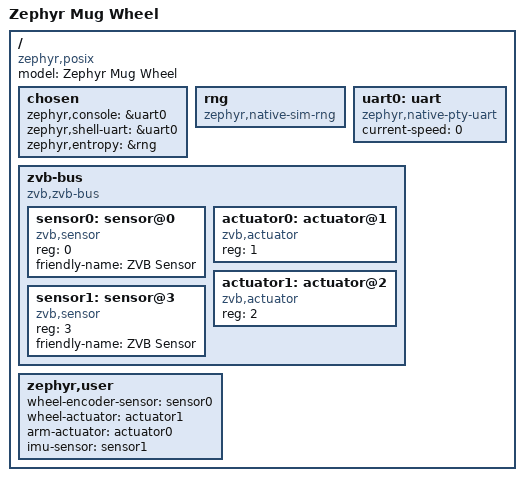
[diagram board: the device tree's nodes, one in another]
/*
 * Copyright 2025 Nordic Semiconductor ASA
 *
 * SPDX-License-Identifier: Apache-2.0
 */

/dts-v1/;
#include <posix/posix.dtsi>

/ {
	model = "Zephyr Mug Wheel";
	compatible = "zephyr,posix";

	chosen {
		zephyr,console = &uart0;
		zephyr,shell-uart = &uart0;
		zephyr,entropy = &rng;
	};

	rng: rng {
		status = "okay";
		compatible = "zephyr,native-sim-rng";
	};

	uart0: uart {
		status = "okay";
		compatible = "zephyr,native-pty-uart";
		current-speed = <0>;
	};

	zvb-bus {
		compatible = "zvb,zvb-bus";
		#address-cells = <1>;
		#size-cells = <0>;

		sensor0: sensor@0 {
			reg = <0>;
			compatible = "zvb,sensor";
			friendly-name = "ZVB Sensor";
		};

		actuator0: actuator@1 {
			reg = <1>;
			compatible = "zvb,actuator";
		};

		actuator1: actuator@2 {
			reg = <2>;
			compatible = "zvb,actuator";
		};

		sensor1: sensor@3 {
			reg = <3>;
			compatible = "zvb,sensor";
			friendly-name = "ZVB Sensor";
		};
	};

	zephyr,user {
		wheel-encoder-sensor = <&sensor0>;
		wheel-actuator = <&actuator1>;
		arm-actuator = <&actuator0>;
		imu-sensor = <&sensor1>;
	};
};
